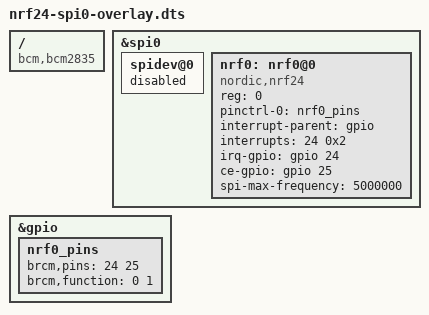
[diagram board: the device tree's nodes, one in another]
// SPDX-License-Identifier: GPL-2.0

//
// Copyright (C) 2017 Marcin Ciupak <marcin.s.ciupak@gmail.com>
//

// Definitions for NRF24
/dts-v1/;
/plugin/;

/ {
	compatible = "bcm,bcm2835", "bcm,bcm2708", "bcm,bcm2709";

	fragment@0 {
		target = <&spi0>;
		__overlay__ {
			#address-cells = <1>;
			#size-cells = <0>;
			status = "okay";

			spidev@0 {
				status = "disabled";
			};

			nrf0: nrf0@0 {
				compatible = "nordic,nrf24";
				reg = <0>; /* CS0 */
				pinctrl-names = "default";
				pinctrl-0 = <&nrf0_pins>;
				interrupt-parent = <&gpio>;
				interrupts = <24 0x2>; /* falling edge */
				irq-gpio = <&gpio 24 0>;
				ce-gpio = <&gpio 25 0>;
				spi-max-frequency = <5000000>;
				status = "okay";
			};
		};
	};

	fragment@1 {
		target = <&gpio>;
		__overlay__ {
			nrf0_pins: nrf0_pins {
				brcm,pins = <24 25>;
				brcm,function = <0 1>; /* in out */
			};
		};
	};

	__overrides__ {
		int_pin = <&nrf0>, "interrupts:0", <&nrf0_pins>, "brcm,pins:0";
		speed   = <&nrf0>, "spi-max-frequency:0";
	};
};
